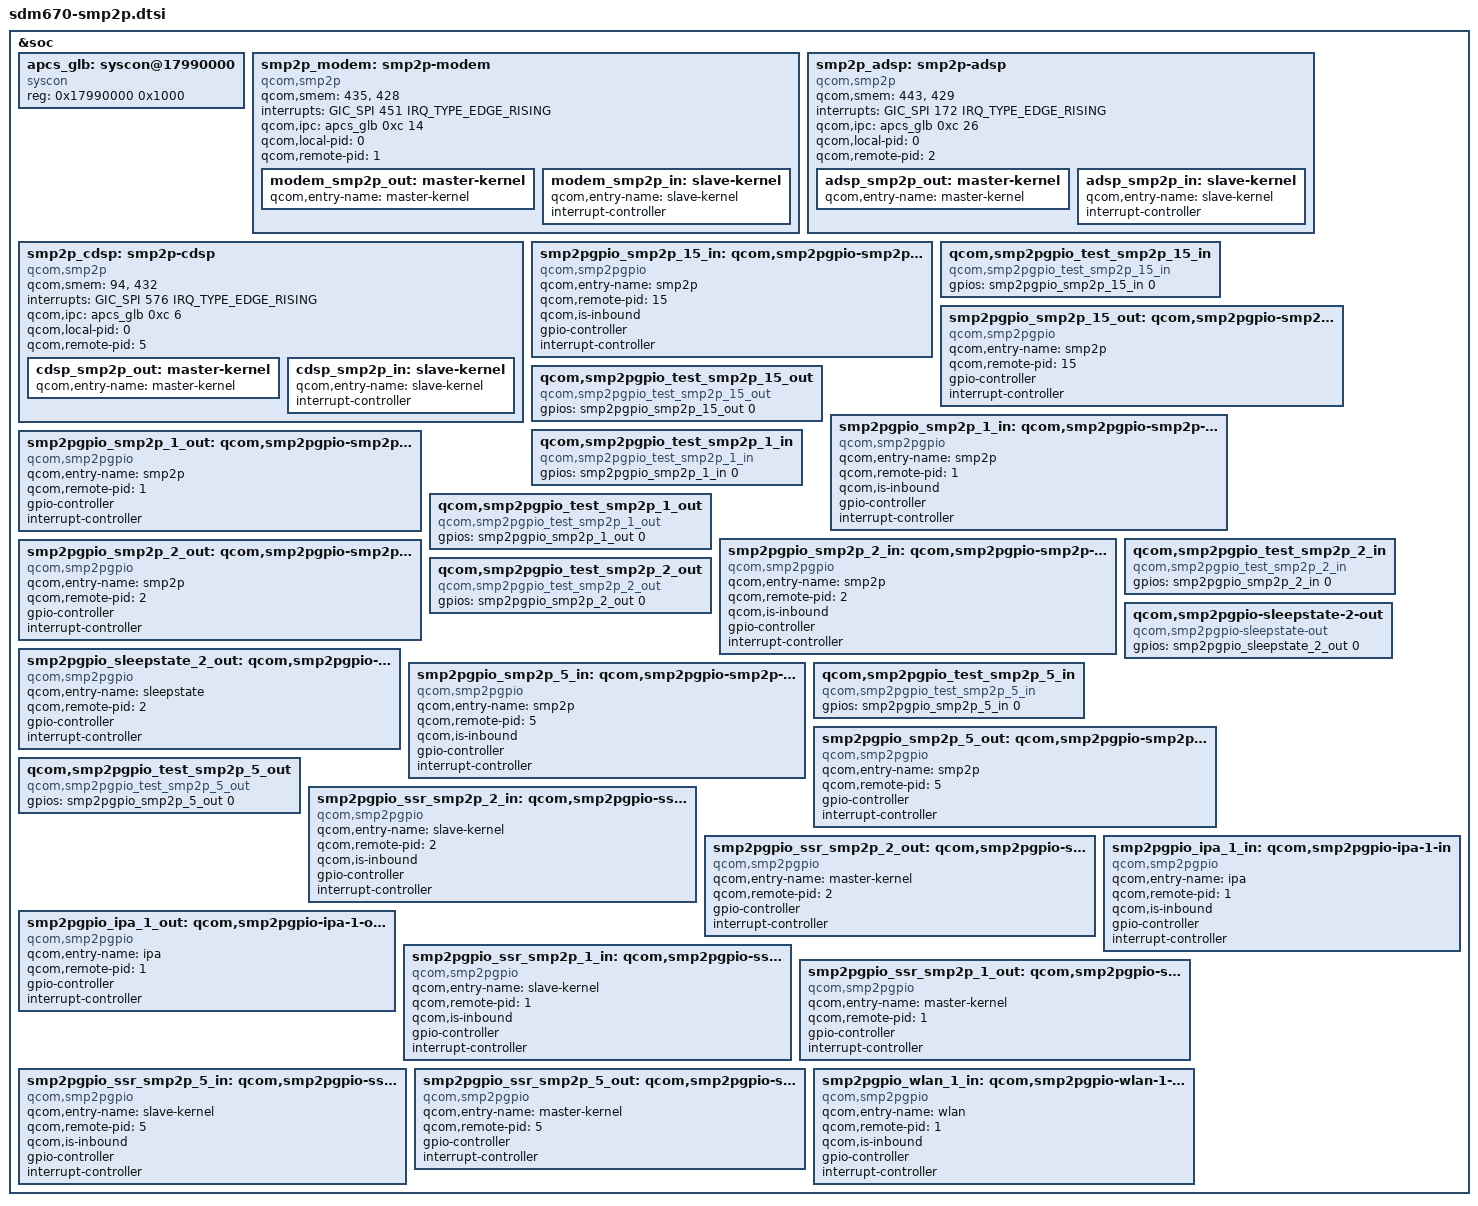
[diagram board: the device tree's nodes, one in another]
/* Copyright (c) 2017-2018, The Linux Foundation. All rights reserved.
 *
 * This program is free software; you can redistribute it and/or modify
 * it under the terms of the GNU General Public License version 2 and
 * only version 2 as published by the Free Software Foundation.
 *
 * This program is distributed in the hope that it will be useful,
 * but WITHOUT ANY WARRANTY; without even the implied warranty of
 * MERCHANTABILITY or FITNESS FOR A PARTICULAR PURPOSE.  See the
 * GNU General Public License for more details.
 */

#include <dt-bindings/interrupt-controller/arm-gic.h>

&soc {
	/* APCS outbound doorbell register (0x1799000c) exposed as a syscon so
	 * the smp2p devices can kick the remote processors via qcom,ipc. */
	apcs_glb: syscon@17990000 {
		compatible = "syscon";
		reg = <0x17990000 0x1000>;
	};

	/* Mainline qcom,smp2p binding. The CLO msm_smp2p form (reg +
	 * qcom,irq-bitmask) has no 7.3 driver; doorbell bits and GIC lines
	 * are carried over from the CLO nodes, smem item ids follow the
	 * SMEM_SMP2P_*_BASE + pid layout shared across this SoC family. */
	smp2p_modem: smp2p-modem {
		compatible = "qcom,smp2p";
		qcom,smem = <435>, <428>;
		interrupts = <GIC_SPI 451 IRQ_TYPE_EDGE_RISING>;
		qcom,ipc = <&apcs_glb 0xc 14>;
		qcom,local-pid = <0>;
		qcom,remote-pid = <1>;

		modem_smp2p_out: master-kernel {
			qcom,entry-name = "master-kernel";
			#qcom,smem-state-cells = <1>;
		};

		modem_smp2p_in: slave-kernel {
			qcom,entry-name = "slave-kernel";
			interrupt-controller;
			#interrupt-cells = <2>;
		};
	};

	smp2p_adsp: smp2p-adsp {
		compatible = "qcom,smp2p";
		qcom,smem = <443>, <429>;
		interrupts = <GIC_SPI 172 IRQ_TYPE_EDGE_RISING>;
		qcom,ipc = <&apcs_glb 0xc 26>;
		qcom,local-pid = <0>;
		qcom,remote-pid = <2>;

		adsp_smp2p_out: master-kernel {
			qcom,entry-name = "master-kernel";
			#qcom,smem-state-cells = <1>;
		};

		adsp_smp2p_in: slave-kernel {
			qcom,entry-name = "slave-kernel";
			interrupt-controller;
			#interrupt-cells = <2>;
		};
	};

	smp2p_cdsp: smp2p-cdsp {
		compatible = "qcom,smp2p";
		qcom,smem = <94>, <432>;
		interrupts = <GIC_SPI 576 IRQ_TYPE_EDGE_RISING>;
		qcom,ipc = <&apcs_glb 0xc 6>;
		qcom,local-pid = <0>;
		qcom,remote-pid = <5>;

		cdsp_smp2p_out: master-kernel {
			qcom,entry-name = "master-kernel";
			#qcom,smem-state-cells = <1>;
		};

		cdsp_smp2p_in: slave-kernel {
			qcom,entry-name = "slave-kernel";
			interrupt-controller;
			#interrupt-cells = <2>;
		};
	};


	smp2pgpio_smp2p_15_in: qcom,smp2pgpio-smp2p-15-in {
		compatible = "qcom,smp2pgpio";
		qcom,entry-name = "smp2p";
		qcom,remote-pid = <15>;
		qcom,is-inbound;
		gpio-controller;
		#gpio-cells = <2>;
		interrupt-controller;
		#interrupt-cells = <2>;
	};

	qcom,smp2pgpio_test_smp2p_15_in {
		compatible = "qcom,smp2pgpio_test_smp2p_15_in";
		gpios = <&smp2pgpio_smp2p_15_in 0 0>;
	};

	smp2pgpio_smp2p_15_out: qcom,smp2pgpio-smp2p-15-out {
		compatible = "qcom,smp2pgpio";
		qcom,entry-name = "smp2p";
		qcom,remote-pid = <15>;
		gpio-controller;
		#gpio-cells = <2>;
		interrupt-controller;
		#interrupt-cells = <2>;
	};

	qcom,smp2pgpio_test_smp2p_15_out {
		compatible = "qcom,smp2pgpio_test_smp2p_15_out";
		gpios = <&smp2pgpio_smp2p_15_out 0 0>;
	};

	smp2pgpio_smp2p_1_in: qcom,smp2pgpio-smp2p-1-in {
		compatible = "qcom,smp2pgpio";
		qcom,entry-name = "smp2p";
		qcom,remote-pid = <1>;
		qcom,is-inbound;
		gpio-controller;
		#gpio-cells = <2>;
		interrupt-controller;
		#interrupt-cells = <2>;
	};

	qcom,smp2pgpio_test_smp2p_1_in {
		compatible = "qcom,smp2pgpio_test_smp2p_1_in";
		gpios = <&smp2pgpio_smp2p_1_in 0 0>;
	};

	smp2pgpio_smp2p_1_out: qcom,smp2pgpio-smp2p-1-out {
		compatible = "qcom,smp2pgpio";
		qcom,entry-name = "smp2p";
		qcom,remote-pid = <1>;
		gpio-controller;
		#gpio-cells = <2>;
		interrupt-controller;
		#interrupt-cells = <2>;
	};

	qcom,smp2pgpio_test_smp2p_1_out {
		compatible = "qcom,smp2pgpio_test_smp2p_1_out";
		gpios = <&smp2pgpio_smp2p_1_out 0 0>;
	};

	smp2pgpio_smp2p_2_in: qcom,smp2pgpio-smp2p-2-in {
		compatible = "qcom,smp2pgpio";
		qcom,entry-name = "smp2p";
		qcom,remote-pid = <2>;
		qcom,is-inbound;
		gpio-controller;
		#gpio-cells = <2>;
		interrupt-controller;
		#interrupt-cells = <2>;
	};

	qcom,smp2pgpio_test_smp2p_2_in {
		compatible = "qcom,smp2pgpio_test_smp2p_2_in";
		gpios = <&smp2pgpio_smp2p_2_in 0 0>;
	};

	smp2pgpio_smp2p_2_out: qcom,smp2pgpio-smp2p-2-out {
		compatible = "qcom,smp2pgpio";
		qcom,entry-name = "smp2p";
		qcom,remote-pid = <2>;
		gpio-controller;
		#gpio-cells = <2>;
		interrupt-controller;
		#interrupt-cells = <2>;
	};

	qcom,smp2pgpio_test_smp2p_2_out {
		compatible = "qcom,smp2pgpio_test_smp2p_2_out";
		gpios = <&smp2pgpio_smp2p_2_out 0 0>;
	};

	smp2pgpio_sleepstate_2_out: qcom,smp2pgpio-sleepstate-gpio-2-out {
		compatible = "qcom,smp2pgpio";
		qcom,entry-name = "sleepstate";
		qcom,remote-pid = <2>;
		gpio-controller;
		#gpio-cells = <2>;
		interrupt-controller;
		#interrupt-cells = <2>;
	};

	qcom,smp2pgpio-sleepstate-2-out {
		compatible = "qcom,smp2pgpio-sleepstate-out";
		gpios = <&smp2pgpio_sleepstate_2_out 0 0>;
	};

	smp2pgpio_smp2p_5_in: qcom,smp2pgpio-smp2p-5-in {
		compatible = "qcom,smp2pgpio";
		qcom,entry-name = "smp2p";
		qcom,remote-pid = <5>;
		qcom,is-inbound;
		gpio-controller;
		#gpio-cells = <2>;
		interrupt-controller;
		#interrupt-cells = <2>;
	};

	qcom,smp2pgpio_test_smp2p_5_in {
		compatible = "qcom,smp2pgpio_test_smp2p_5_in";
		gpios = <&smp2pgpio_smp2p_5_in 0 0>;
	};

	smp2pgpio_smp2p_5_out: qcom,smp2pgpio-smp2p-5-out {
		compatible = "qcom,smp2pgpio";
		qcom,entry-name = "smp2p";
		qcom,remote-pid = <5>;
		gpio-controller;
		#gpio-cells = <2>;
		interrupt-controller;
		#interrupt-cells = <2>;
	};

	qcom,smp2pgpio_test_smp2p_5_out {
		compatible = "qcom,smp2pgpio_test_smp2p_5_out";
		gpios = <&smp2pgpio_smp2p_5_out 0 0>;
	};

	/* ssr - inbound entry from lpass */
	smp2pgpio_ssr_smp2p_2_in: qcom,smp2pgpio-ssr-smp2p-2-in {
		compatible = "qcom,smp2pgpio";
		qcom,entry-name = "slave-kernel";
		qcom,remote-pid = <2>;
		qcom,is-inbound;
		gpio-controller;
		#gpio-cells = <2>;
		interrupt-controller;
		#interrupt-cells = <2>;
	};

	/* ssr - outbound entry to lpass */
	smp2pgpio_ssr_smp2p_2_out: qcom,smp2pgpio-ssr-smp2p-2-out {
		compatible = "qcom,smp2pgpio";
		qcom,entry-name = "master-kernel";
		qcom,remote-pid = <2>;
		gpio-controller;
		#gpio-cells = <2>;
		interrupt-controller;
		#interrupt-cells = <2>;
	};

	/* ipa - outbound entry to mss */
	smp2pgpio_ipa_1_out: qcom,smp2pgpio-ipa-1-out {
		compatible = "qcom,smp2pgpio";
		qcom,entry-name = "ipa";
		qcom,remote-pid = <1>;
		gpio-controller;
		#gpio-cells = <2>;
		interrupt-controller;
		#interrupt-cells = <2>;
	};

	/* ipa - inbound entry from mss */
	smp2pgpio_ipa_1_in: qcom,smp2pgpio-ipa-1-in {
		compatible = "qcom,smp2pgpio";
		qcom,entry-name = "ipa";
		qcom,remote-pid = <1>;
		qcom,is-inbound;
		gpio-controller;
		#gpio-cells = <2>;
		interrupt-controller;
		#interrupt-cells = <2>;
	};

	/* ssr - inbound entry from mss */
	smp2pgpio_ssr_smp2p_1_in: qcom,smp2pgpio-ssr-smp2p-1-in {
		compatible = "qcom,smp2pgpio";
		qcom,entry-name = "slave-kernel";
		qcom,remote-pid = <1>;
		qcom,is-inbound;
		gpio-controller;
		#gpio-cells = <2>;
		interrupt-controller;
		#interrupt-cells = <2>;
	};

	/* ssr - outbound entry to mss */
	smp2pgpio_ssr_smp2p_1_out: qcom,smp2pgpio-ssr-smp2p-1-out {
		compatible = "qcom,smp2pgpio";
		qcom,entry-name = "master-kernel";
		qcom,remote-pid = <1>;
		gpio-controller;
		#gpio-cells = <2>;
		interrupt-controller;
		#interrupt-cells = <2>;
	};

	/* ssr - inbound entry from cdsp */
	smp2pgpio_ssr_smp2p_5_in: qcom,smp2pgpio-ssr-smp2p-5-in {
		compatible = "qcom,smp2pgpio";
		qcom,entry-name = "slave-kernel";
		qcom,remote-pid = <5>;
		qcom,is-inbound;
		gpio-controller;
		#gpio-cells = <2>;
		interrupt-controller;
		#interrupt-cells = <2>;
	};

	/* ssr - outbound entry to cdsp */
	smp2pgpio_ssr_smp2p_5_out: qcom,smp2pgpio-ssr-smp2p-5-out {
		compatible = "qcom,smp2pgpio";
		qcom,entry-name = "master-kernel";
		qcom,remote-pid = <5>;
		gpio-controller;
		#gpio-cells = <2>;
		interrupt-controller;
		#interrupt-cells = <2>;
	};

	/* wlan - inbound entry from mss/WLAN PD */
	smp2pgpio_wlan_1_in: qcom,smp2pgpio-wlan-1-in {
		compatible = "qcom,smp2pgpio";
		qcom,entry-name = "wlan";
		qcom,remote-pid = <1>;
		qcom,is-inbound;
		gpio-controller;
		#gpio-cells = <2>;
		interrupt-controller;
		#interrupt-cells = <2>;
	};
};
